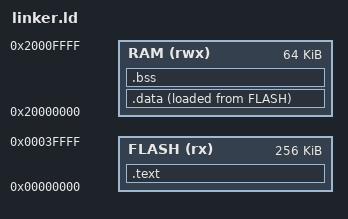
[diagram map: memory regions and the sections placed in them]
MEMORY
{
  FLASH (rx)  : ORIGIN = 0x00000000, LENGTH = 256K
  RAM   (rwx) : ORIGIN = 0x20000000, LENGTH = 64K
}

SECTIONS
{
  .text :
  {
    KEEP(*(.isr_vector))
    *(.text*)
    *(.rodata*)
  } > FLASH

  _sidata = LOADADDR(.data);

  .data :
  {
    _sdata = .;
    *(.data*)
    _edata = .;
  } > RAM AT> FLASH

  .bss :
  {
    _sbss = .;
    *(.bss*)
    *(COMMON)
    _ebss = .;
  } > RAM

  . = ALIGN(8);
  PROVIDE(end = .);
  PROVIDE(_end = .);
  _estack = ORIGIN(RAM) + LENGTH(RAM);
}
